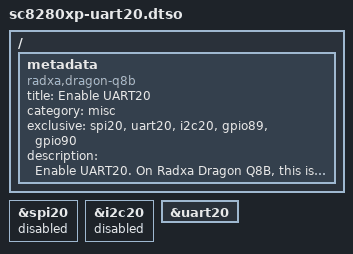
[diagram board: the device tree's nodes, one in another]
// SPDX-License-Identifier: BSD-3-Clause
/*
 * Copyright (c) 2026 Radxa Computer (Shenzhen) Co., Ltd.
 */

/dts-v1/;
/plugin/;

/ {
	metadata {
		title = "Enable UART20";
		compatible = "radxa,dragon-q8b";
		category = "misc";
		exclusive = "spi20", "uart20", "i2c20", "gpio89", "gpio90";
		description = "Enable UART20.
On Radxa Dragon Q8B, this is pin 23(tx), 24(rx).";
	};
};

&spi20 {
	status = "disabled";
};

&i2c20 {
	status = "disabled";
};

&uart20 {
	status = "okay";
};
